AUTOSAR XML (schema 4-0-3)
package /PATAC/MSM/ComponentTypes
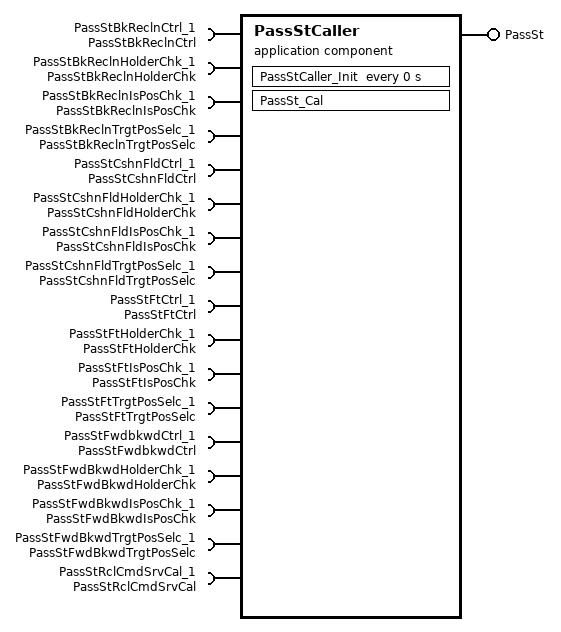
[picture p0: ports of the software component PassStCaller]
  application sw component type PassStCaller
    provide port PassSt: server-com-spec{operation=PassSt/Cal, queue-length=1}, provided-interface=PassSt
    17 x require port:
      PassStBkReclnCtrl_1: client-com-spec=PassStBkReclnCtrl/Cal, required-interface=PassStBkReclnCtrl
      PassStBkReclnHolderChk_1: client-com-spec=PassStBkReclnHolderChk/Cal, required-interface=PassStBkReclnHolderChk
      PassStBkReclnIsPosChk_1: client-com-spec=PassStBkReclnIsPosChk/Cal, required-interface=PassStBkReclnIsPosChk
      PassStBkReclnTrgtPosSelc_1: client-com-spec=PassStBkReclnTrgtPosSelc/Cal, required-interface=PassStBkReclnTrgtPosSelc
      PassStCshnFldCtrl_1: client-com-spec=PassStCshnFldCtrl/Cal, required-interface=PassStCshnFldCtrl
      PassStCshnFldHolderChk_1: client-com-spec=PassStCshnFldHolderChk/Cal, required-interface=PassStCshnFldHolderChk
      PassStCshnFldIsPosChk_1: client-com-spec=PassStCshnFldIsPosChk/Cal, required-interface=PassStCshnFldIsPosChk
      PassStCshnFldTrgtPosSelc_1: client-com-spec=PassStCshnFldTrgtPosSelc/Cal, required-interface=PassStCshnFldTrgtPosSelc
      PassStFtCtrl_1: client-com-spec=PassStFtCtrl/Cal, required-interface=PassStFtCtrl
      PassStFtHolderChk_1: client-com-spec=PassStFtHolderChk/Cal, required-interface=PassStFtHolderChk
      PassStFtIsPosChk_1: client-com-spec=PassStFtIsPosChk/Cal, required-interface=PassStFtIsPosChk
      PassStFtTrgtPosSelc_1: client-com-spec=PassStFtTrgtPosSelc/Cal, required-interface=PassStFtTrgtPosSelc
      PassStFwdbkwdCtrl_1: client-com-spec=PassStFwdbkwdCtrl/Cal, required-interface=PassStFwdbkwdCtrl
      PassStFwdBkwdHolderChk_1: client-com-spec=PassStFwdBkwdHolderChk/Cal, required-interface=PassStFwdBkwdHolderChk
      PassStFwdBkwdIsPosChk_1: client-com-spec=PassStFwdBkwdIsPosChk/Cal, required-interface=PassStFwdBkwdIsPosChk
      PassStFwdBkwdTrgtPosSelc_1: client-com-spec=PassStFwdBkwdTrgtPosSelc/Cal, required-interface=PassStFwdBkwdTrgtPosSelc
      PassStRclCmdSrvCal_1: client-com-spec=PassStRclCmdSrvCal/Cal, required-interface=PassStRclCmdSrvCal
    behavior PassStCaller_InternalBehavior
      operation invoked event OIT_PassSt_Cal_PassSt_Cal: start-on-event=PassSt_Cal, operation=PassSt.Cal
      timing event PassStCaller_InitEvent: start-on-event=PassStCaller_Init, period=0
      runnable PassSt_Cal
        17 x sync call, all with timeout=0:
          SC_PassStBkReclnCtrl_1_Cal: operation=PassStBkReclnCtrl_1.Cal
          SC_PassStBkReclnHolderChk_1_Cal: operation=PassStBkReclnHolderChk_1.Cal
          SC_PassStBkReclnIsPosChk_1_Cal: operation=PassStBkReclnIsPosChk_1.Cal
          SC_PassStBkReclnTrgtPosSelc_1_Cal: operation=PassStBkReclnTrgtPosSelc_1.Cal
          SC_PassStCshnFldCtrl_1_Cal: operation=PassStCshnFldCtrl_1.Cal
          SC_PassStCshnFldHolderChk_1_Cal: operation=PassStCshnFldHolderChk_1.Cal
          SC_PassStCshnFldIsPosChk_1_Cal: operation=PassStCshnFldIsPosChk_1.Cal
          SC_PassStCshnFldTrgtPosSelc_1_Cal: operation=PassStCshnFldTrgtPosSelc_1.Cal
          SC_PassStFtCtrl_1_Cal: operation=PassStFtCtrl_1.Cal
          SC_PassStFtHolderChk_1_Cal: operation=PassStFtHolderChk_1.Cal
          SC_PassStFtIsPosChk_1_Cal: operation=PassStFtIsPosChk_1.Cal
          SC_PassStFtTrgtPosSelc_1_Cal: operation=PassStFtTrgtPosSelc_1.Cal
          SC_PassStFwdbkwdCtrl_1_Cal: operation=PassStFwdbkwdCtrl_1.Cal
          SC_PassStFwdBkwdHolderChk_1_Cal: operation=PassStFwdBkwdHolderChk_1.Cal
          SC_PassStFwdBkwdIsPosChk_1_Cal: operation=PassStFwdBkwdIsPosChk_1.Cal
          SC_PassStFwdBkwdTrgtPosSelc_1_Cal: operation=PassStFwdBkwdTrgtPosSelc_1.Cal
          SC_PassStRclCmdSrvCal_1_Cal: operation=PassStRclCmdSrvCal_1.Cal
      runnable PassStCaller_Init
  swc implementation PassStCaller_Implementation: behavior=PassStCaller_InternalBehavior
    code-descriptors:
      code Default: artifact-descriptors=autosar-engineering-object={short-label=Default, category=SWSRC}
package /PATAC/MSM/ModeAdjust/PortInterface
  18 x client server interface:
    PassSt
      operation Cal
    PassStBkReclnCtrl
      operation Cal
    PassStBkReclnHolderChk
      operation Cal
    PassStBkReclnIsPosChk
      operation Cal
    PassStBkReclnTrgtPosSelc
      operation Cal
    PassStCshnFldCtrl
      operation Cal
    PassStCshnFldHolderChk
      operation Cal
    PassStCshnFldIsPosChk
      operation Cal
    PassStCshnFldTrgtPosSelc
      operation Cal
    PassStFtCtrl
      operation Cal
    PassStFtHolderChk
      operation Cal
    PassStFtIsPosChk
      operation Cal
    PassStFtTrgtPosSelc
      operation Cal
    PassStFwdbkwdCtrl
      operation Cal
    PassStFwdBkwdHolderChk
      operation Cal
    PassStFwdBkwdIsPosChk
      operation Cal
    PassStFwdBkwdTrgtPosSelc
      operation Cal
    PassStRclCmdSrvCal
      operation Cal
